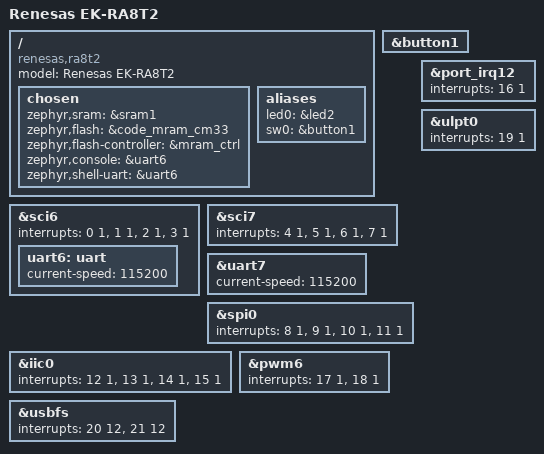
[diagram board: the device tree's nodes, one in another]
/*
 * Copyright (c) 2026 Renesas Electronics Corporation
 * SPDX-License-Identifier: Apache-2.0
 */

/dts-v1/;

#include <renesas/ra/ra8/r7ka8t2lflcac_cm33.dtsi>
#include "ek_ra8t2.dtsi"

/ {
	model = "Renesas EK-RA8T2";
	compatible = "renesas,ra8t2", "renesas,ra8";

	chosen {
		zephyr,sram = &sram1;
		zephyr,flash = &code_mram_cm33;
		zephyr,flash-controller = &mram_ctrl;
		zephyr,console = &uart6;
		zephyr,shell-uart = &uart6;
	};

	aliases {
		led0 = &led2;
		sw0 = &button1;
	};
};

&button1 {
	status = "okay";
};

&sci6 {
	interrupts = <0 1>, <1 1>, <2 1>, <3 1>;
	interrupt-names = "rxi", "txi", "tei", "eri";
	status = "okay";

	uart6: uart {
		current-speed = <115200>;
		status = "okay";
	};
};

&sci7 {
	interrupts = <4 1>, <5 1>, <6 1>, <7 1>;
	interrupt-names = "rxi", "txi", "tei", "eri";
};

&uart7 {
	current-speed = <115200>;
};

&spi0 {
	interrupts = <8 1>, <9 1>, <10 1>, <11 1>;
	interrupt-names = "rxi", "txi", "tei", "eri";
};

&iic0 {
	interrupts = <12 1>, <13 1>, <14 1>, <15 1>;
	interrupt-names = "rxi", "txi", "tei", "eri";
};

&port_irq12 {
	interrupts = <16 1>;
	status = "okay";
};

&pwm6 {
	interrupts = <17 1>, <18 1>;
	interrupt-names = "gtioca", "overflow";
};

&ulpt0 {
	interrupts = <19 1>;
	interrupt-names = "ulpti";
};

&usbfs {
	interrupts = <20 12>, <21 12>;
	interrupt-names = "usbfs-i", "usbfs-r";
};
